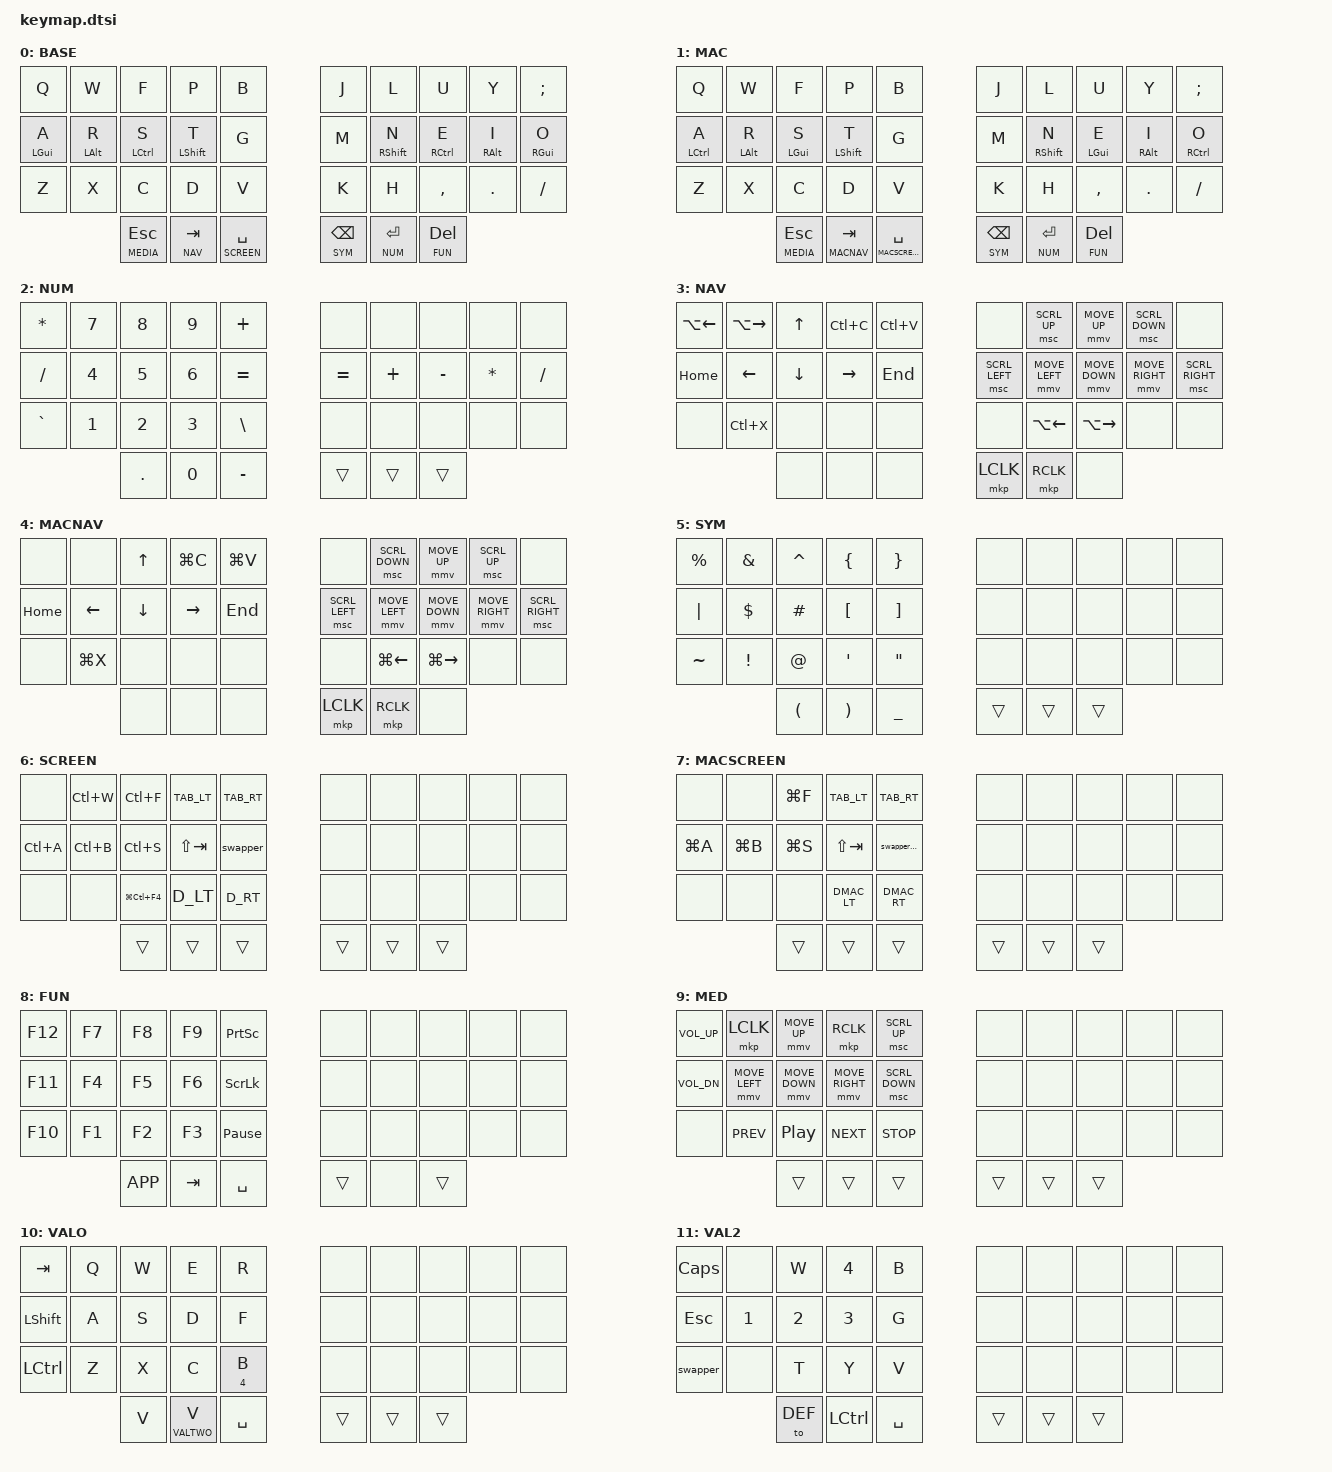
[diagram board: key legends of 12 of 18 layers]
 /*
 * Copyright (c) 2020 The ZMK Contributors
 *
 * SPDX-License-Identifier: MIT
 */

#include <behaviors.dtsi>
#include "zmk-helpers/helper.h"
#include <dt-bindings/zmk/keys.h>
#include <dt-bindings/zmk/bt.h>
#include <dt-bindings/zmk/outputs.h>
#include <dt-bindings/zmk/ext_power.h>


#include <dt-bindings/zmk/bt.h>

// #define _BT_SEL_KEYS_ &bt BT_SEL 0 &bt BT_SEL 1 &bt BT_SEL 2 &bt BT_SEL 3


#define DEF 0
#define MAC 1
#define NUM 2
#define NAV 3
#define MACNAV 4
#define SYM 5
#define SCREEN 6
#define MACSCREEN 7
#define FUN 8
#define MEDIA 9
#define VAL 10
#define VALTWO 11
#define EXTRA 12
#define TAP 13
#define MOUSE_KEYS 14
#define MOUSE_TP 15
#define MOUSE_TP_SET 16
#define SYS 17


/*
 * Defines to enable/disable features
 *
 * These defines allow us to conditionally enable and disable parts of the keymap config.
 *
 * For example, if we decide to build the firmware without the mouse features, we can
 * disable all the config options that rely on those forks and modules without having
 * to edit the entire keymap file manually every time.
 */

#define HAS_MOUSE_KEYS
#define HAS_MOUSE_TP

#ifdef HAS_MOUSE_KEYS
  #include <dt-bindings/zmk/mouse.h>
  #include <behaviors/mouse_keys.dtsi>
#endif  // HAS_MOUSE_KEYS

#ifdef HAS_MOUSE_TP
  // We store the trackpoint settings in a separate file
  // to make organization a little easier.
  #include "mouse_tp.dtsi"
#endif  // HAS_MOUSE_TP



// Adjust layer keys based on enabled features.
//
// This prevents build errors when we build the firmware
// without the mouse keys PR or the TP module.
#ifdef HAS_MOUSE_KEYS
  #define U_THUMB_INNER &mo MOUSE_KEYS
#else
  #define U_THUMB_INNER &none
#endif  // HAS_MOUSE_KEYS

#ifdef HAS_MOUSE_TP
  #define U_TOG_TP_SET &tog MOUSE_TP_SET
#else
  #define U_TOG_TP_SET &none
#endif  // HAS_MOUSE_TP


// Desktop and tab navigation shortcuts
#define D_LT   LC(LG(LEFT))
#define D_RT   LC(LG(RIGHT))
#define D_CL   LC(LG(F4))

//Mac desktop navigation shortcuts
#define DMAC_LT   LC(LEFT)
#define DMAC_RT   LC(RIGHT)

#define TAB_RT LC(TAB)
#define TAB_LT LC(LS(TAB))

// Extra key bindings
#define SWP_POS 13

&lt { quick_tap_ms = <250>; };
&lt { quick_tap_ms = <250>; };


#define QUICK_TAP_MS 175
#define TAPPING_TERM_MS 175

/* Timeless homerow mods */

// https://github.com/urob/zmk-config/tree/main#timeless-homerow-mods
#define KEYS_L LT0 LT1 LT2 LT3 LT4 LM0 LM1 LM2 LM3 LM4 LB0 LB1 LB2 LB3 LB4  // left hand
#define KEYS_R RT0 RT1 RT2 RT3 RT4 RM0 RM1 RM2 RM3 RM4 RB0 RB1 RB2 RB3 RB4  // right hand
#define THUMBS LH2 LH1 LH0 RH0 RH1 RH2                                      // thumbs

ZMK_HOLD_TAP(hml,
    flavor = "balanced";
    tapping-term-ms = <TAPPING_TERM_MS>;
    quick-tap-ms = <QUICK_TAP_MS>;
    require-prior-idle-ms = <150>;
    hold-trigger-key-positions = <KEYS_R THUMBS>;
    hold-trigger-on-release;
    bindings = <&kp>, <&kp>;
)

ZMK_HOLD_TAP(hmr,
    flavor = "balanced";
    tapping-term-ms = <TAPPING_TERM_MS>;
    quick-tap-ms = <QUICK_TAP_MS>;
    require-prior-idle-ms = <150>;
    hold-trigger-key-positions = <KEYS_L THUMBS>;
    hold-trigger-on-release;
    bindings = <&kp>, <&kp>;
)

#define QUICK_TAP_MS 175
/* Homerow mods */

/ {
    behaviors {
        bhm: balanced_homerow_mods {
            compatible = "zmk,behavior-hold-tap";
            #binding-cells = <2>;
            tapping-term-ms = <200>;    // <---[[moderate duration]]
            quick-tap-ms = <0>;
            flavor = "balanced";
            bindings = <&kp>, <&kp>;
        };
        // Swapper for smart alt+tab
        swapper: swapper {
            compatible = "zmk,behavior-tri-state";
            #binding-cells = <0>;
            bindings = <&kt LALT>, <&kp TAB>, <&kt LALT>;
            ignored-key-positions = <SWP_POS>;
        };
        swappermac: swappermac {
            compatible = "zmk,behavior-tri-state";
            #binding-cells = <0>;
            bindings = <&kt LGUI>, <&kp TAB>, <&kt LGUI>;
            ignored-key-positions = <SWP_POS>;
        };
    };
};
/ {
    conditional_layers {
        compatible = "zmk,conditional-layers";
        tri_layer {
            if-layers = <5 6>;
            then-layer = <14>;
        };
    };
};

/ {
    conditional_layers1 {
        compatible = "zmk,conditional-layers";
        tri_layer {
            if-layers = <5 7>;
            then-layer = <14>;
        };
    };
};

/ {
    macros {
        numdot: numdot {
            label = "ZM_numdot";
            compatible = "zmk,behavior-macro";
            #binding-cells = <0>;
            wait-ms = <40>;
            tap-ms = <40>;
            bindings
                = <&macro_press   &kp LALT>    
                , <&macro_tap     &kp KP_N4 &kp KP_N6>    
                , <&macro_release &kp LALT>
                ;
        };
        grtsgn: grtsgn {
            label = "ZM_grtsgn";
            compatible = "zmk,behavior-macro";
            #binding-cells = <0>;
            wait-ms = <40>;
            tap-ms = <40>;
            bindings
                = <&macro_press   &kp LALT>    
                , <&macro_tap     &kp KP_N6 &kp KP_N2>    
                , <&macro_release &kp LALT>
                ;
        };
    };
};

#include "combos.dtsi"

/ {
        keymap {
                compatible = "zmk,keymap";

                default_layer {  
                label = "BASE"; //DEFAULT
                bindings = <
                &kp Q                 &kp W         &kp F             &kp P             &kp B                      &kp J            &kp L              &kp U           &kp Y           &kp SEMI        
                &hml LGUI A           &hml LALT R   &hml LCTRL S      &hml LSHFT T      &kp G                      &kp M            &hmr RSHFT N       &hmr RCTRL E    &hmr RALT I     &hmr RGUI O     
                &kp Z                 &kp X         &kp C             &kp D             &kp V                      &kp K            &kp H              &kp COMMA       &kp DOT         &kp FSLH        
                                                    &lt MEDIA ESC     &lt NAV TAB       &lt SCREEN SPACE            &lt SYM BSPC     &lt NUM RET        &lt FUN DEL
                        >;
                };
                mac_layer {  
                label = "MAC"; //MAC DEFAULT
                bindings = <
                &kp Q                 &kp W         &kp F             &kp P             &kp B                      &kp J            &kp L              &kp U           &kp Y           &kp SEMI        
                &hml LCTRL A          &hml LALT R   &hml LGUI S       &hml LSHFT T      &kp G                      &kp M            &hmr RSHFT N       &hmr LGUI E     &hmr RALT I     &hmr RCTRL O     
                &kp Z                 &kp X         &kp C             &kp D             &kp V                      &kp K            &kp H              &kp COMMA       &kp DOT         &kp FSLH        
                                                    &lt MEDIA ESC     &lt MACNAV TAB       &lt MACSCREEN SPACE        &lt SYM BSPC     &lt NUM RET        &lt FUN DEL
                        >;
                };
                num_layer {    
                label = "NUM"; //NUM
                
                bindings = <
                &kp ASTRK             &kp N7        &kp N8            &kp N9            &kp PLUS                   &none            &none              &none           &none           &none           
                &kp SLASH             &kp N4        &kp N5            &kp N6            &kp EQUAL                  &kp EQUAL        &kp PLUS           &kp MINUS       &kp ASTRK       &kp SLASH            
                &kp GRAVE             &kp N1        &kp N2            &kp N3            &kp BSLH                   &none            &none              &none           &none           &none           
                                                    &kp DOT           &kp N0            &kp MINUS                  &trans           &trans             &trans
                        >;
                };
                nav_layer {    
                label = "NAV"; //NAV
                bindings = <
                &kp LA(LEFT)      &kp LA(RIGHT)     &kp UP            &kp LC(C)         &kp LC(V)                  &none            &msc SCRL_UP       &mmv MOVE_UP    &msc SCRL_DOWN  &none                
                &kp HOME              &kp LEFT      &kp DOWN          &kp RIGHT         &kp END                    &msc SCRL_LEFT   &mmv MOVE_LEFT     &mmv MOVE_DOWN  &mmv MOVE_RIGHT &msc SCRL_RIGHT           
                &none                 &kp LC(X)     &none             &none             &none                      &none            &kp LA(LEFT)       &kp LA(RIGHT)   &none           &none           
                                                    &none             &none             &none                      &mkp LCLK        &mkp RCLK          &none
                        >;  
                };
                macnav_layer {    
                label = "MACNAV"; //NAV
                bindings = <
                &none                     &none     &kp UP            &kp LG(C)         &kp LG(V)                  &none            &msc SCRL_DOWN     &mmv MOVE_UP    &msc SCRL_UP    &none                
                &kp HOME              &kp LEFT      &kp DOWN          &kp RIGHT         &kp END                    &msc SCRL_LEFT   &mmv MOVE_LEFT     &mmv MOVE_DOWN  &mmv MOVE_RIGHT &msc SCRL_RIGHT           
                &none                 &kp LG(X)     &none             &none             &none                      &none            &kp LG(LEFT)       &kp LG(RIGHT)   &none           &none                     
                                                    &none             &none             &none                      &mkp LCLK        &mkp RCLK          &none
                        >;  
                };
                sym_layer {   
                label = "SYM"; //SYM
                bindings = <
                &kp PRCNT             &kp AMPS      &kp CARET         &kp LBRC          &kp RBRC                   &none            &none              &none           &none           &none           
                &kp PIPE              &kp DLLR      &kp HASH          &kp LBKT          &kp RBKT                   &none            &none              &none           &none           &none           
                &kp TILDE             &kp EXCL      &kp AT            &kp SQT           &kp DOUBLE_QUOTES          &none            &none              &none           &none           &none           
                                                    &kp LPAR          &kp RPAR          &kp UNDER                  &trans           &trans             &trans 
                        >;
                };
                screen_layer {   
                label = "SCREEN"; //SCREEN
                bindings = <
                &none                   &kp LC(W)   &kp LC(F)         &kp TAB_LT         &kp TAB_RT                &none            &none              &none           &none           &none          
                &kp LC(A)               &kp LC(B)   &kp LC(S)         &kp LS(TAB)        &swapper                  &none            &none              &none           &none           &none         
                &none                   &none       &kp LG(LC(F4))    &kp D_LT           &kp D_RT                  &none            &none              &none           &none           &none          
                                                    &trans            &trans             &trans                    &trans           &trans             &trans
                        >;
                };
                macscreen_layer {   
                label = "MACSCREEN"; //MAC SCREEN
                bindings = <
                &none                   &none       &kp LG(F)         &kp TAB_LT         &kp TAB_RT                &none            &none              &none           &none           &none          
                &kp LG(A)               &kp LG(B)   &kp LG(S)         &kp LS(TAB)        &swappermac               &none            &none              &none           &none           &none         
                &none                   &none       &none             &kp DMAC_LT        &kp DMAC_RT               &none            &none              &none           &none           &none          
                                                    &trans            &trans             &trans                    &trans           &trans             &trans
                        >;
                };
                fun_layer {  
                label = "FUN"; //FUN
                bindings = <
                &kp F12               &kp F7        &kp F8            &kp F9            &kp PSCRN                  &none            &none              &none           &none           &none           
                &kp F11               &kp F4        &kp F5            &kp F6            &kp SLCK                   &none            &none              &none           &none           &none           
                &kp F10               &kp F1        &kp F2            &kp F3            &kp PAUSE_BREAK            &none            &none              &none           &none           &none           
                                                    &kp K_APP         &kp TAB           &kp SPACE                  &trans           &none              &trans
                        >;
                };
                media_layer {  
                label = "MED"; //MEDIA         
                bindings = <
                &kp C_VOL_UP          &mkp LCLK     &mmv MOVE_UP      &mkp RCLK         &msc SCRL_UP               &none            &none              &none           &none           &none           
                &kp C_VOL_DN          &mmv MOVE_LEFT &mmv MOVE_DOWN   &mmv MOVE_RIGHT   &msc SCRL_DOWN             &none            &none              &none           &none           &none           
                &none                 &kp C_PREV    &kp C_PP          &kp C_NEXT        &kp C_STOP                 &none            &none              &none           &none           &none           
                                                    &trans            &trans            &trans                     &trans           &trans             &trans
                        >;
                };
                // media_layer {  
                // label = "MED"; //MEDIA  
                // bindings = <
                // &none                 &none         &kp C_VOL_UP      &none             &kp C_MUTE                 &none            &none              &none           &none           &none           
                // &none                 &kp C_PREV    &kp C_VOL_DN      &kp C_NEXT        &kp C_PP                   &none            &none              &none           &none           &none           
                // &none                 &none         &none             &none             &kp C_STOP                 &none            &none              &none           &none           &none           
                //                                     &trans            &trans            &trans                     &trans           &trans             &trans
                //         >;
                // };

                val_layer {  
                label = "VALO"; //VAL
                bindings = <
                &kp TAB               &kp Q         &kp W             &kp E             &kp R                      &none            &none              &none           &none           &none           
                &kp LSHFT             &kp A         &kp S             &kp D             &kp F                      &none            &none              &none           &none           &none           
                &kp LCTRL             &kp Z         &kp X             &kp C             &bhm N4 B                  &none            &none              &none           &none           &none          
                                                    &kp V             &lt VALTWO V      &kp SPACE                  &trans           &trans             &trans
                        >;
                };
                valtwo_layer {  
                label = "VAL2"; //VALTWO
                bindings = <
                &kp CAPSLOCK         &none          &kp W             &kp N4            &kp B                      &none            &none              &none           &none           &none           
                &kp ESC              &kp N1         &kp N2            &kp N3            &kp G                      &none            &none              &none           &none           &none           
                &swapper             &none          &kp T             &kp Y             &kp V                      &none            &none              &none           &none           &none           
                                                    &to DEF           &kp LCTRL         &kp SPACE                  &trans           &trans             &trans
                        >;
                };
                extra_layer {    
                label = "EXTRA"; //EXTRA
                bindings = <
                &kp Q               &kp W           &kp E             &kp R             &kp T                      &kp Y            &kp U              &kp I           &kp O           &kp P            
                &kp A               &kp S           &kp D             &kp F             &kp G                      &kp H            &kp J              &kp K           &kp L           &kp SEMI        
                &kp Z               &kp X           &kp C             &kp V             &kp B                      &kp N            &kp M              &kp COMMA       &kp DOT         &kp FSLH        
                                                    &kp ESC           &kp TAB           &kp SPACE                  &kp BSPC         &kp RET            &to DEF 
                        >; 
                };
                tap_layer {  
                label = "TAP"; //TAP
                bindings = <
                &kp Q                 &kp W         &kp F             &kp P             &kp B                      &kp J            &kp L              &kp U           &kp Y           &kp SEMI        
                &kp A                 &kp R         &kp S             &kp T             &kp G                      &kp M            &kp N              &kp E           &kp I           &kp O     
                &kp Z                 &kp X         &kp C             &kp D             &kp V                      &kp K            &kp H              &kp COMMA       &kp DOT         &kp FSLH        
                                                    &kp ESC           &kp TAB           &kp SPACE                  &kp BSPC         &kp RET            &kp DEL
                        >;
                };
                sys_layer {    
                label = "SYS"; //SYS
                bindings = <
                &bt BT_CLR          &none           &none             &none             &to DEF                   &to DEF           &none              &none           &none           &bt BT_CLR          
                &none               &none           &none             &none             &to MAC                   &bt BT_SEL 0      &bt BT_SEL 1       &bt BT_SEL 2    &bt BT_SEL 3    &bt BT_SEL 4      
                &bootloader     &ext_power EP_ON    &out OUT_USB      &out OUT_BLE      &sys_reset                &sys_reset        &none              &none      &ext_power EP_ON     &bootloader            
                                                    &trans            &trans            &trans                    &trans            &trans             &trans
                        >; 
                };

                #ifdef HAS_MOUSE_KEYS

    MouseKeys_layer {
      display-name = "MouseKeys";
      bindings = <
// ╭────────────────────────┬────────────────────────┬────────────────────────┬────────────────────────┬────────────────────────┬────────────────────────╮    ╭────────────────────────┬────────────────────────┬────────────────────────┬────────────────────────┬────────────────────────┬────────────────────────╮
     U_TOG_TP_SET             U_TOG_TP_SET             &none                    &mmv MOVE_UP             &msc SCRL_UP             &none                         &none                    &msc SCRL_UP             &mmv MOVE_UP             &none                    U_TOG_TP_SET              U_TOG_TP_SET
// ├────────────────────────┼────────────────────────┼────────────────────────┼────────────────────────┼────────────────────────┼────────────────────────┤    ├────────────────────────┼────────────────────────┼────────────────────────┼────────────────────────┼────────────────────────┼────────────────────────┤
     &trans                   &none                    &mmv MOVE_LEFT           &mmv MOVE_DOWN           &mmv MOVE_RIGHT          &none                         &none                    &mmv MOVE_LEFT           &mmv MOVE_DOWN           &mmv MOVE_RIGHT          &none                     &trans
// ├────────────────────────┼────────────────────────┼────────────────────────┼────────────────────────┼────────────────────────┼────────────────────────┤    ├────────────────────────┼────────────────────────┼────────────────────────┼────────────────────────┼────────────────────────┼────────────────────────┤
     &trans                   &none                    &none                    &none                    &msc SCRL_DOWN           &none                         &none                    &msc SCRL_DOWN           &none                    &none                    &trans                    &trans
// ╰────────────────────────┴────────────────────────┴────────────────────────┴────────────────────────┼────────────────────────┼────────────────────────┤    ├────────────────────────┼────────────────────────┼────────────────────────┼────────────────────────┴────────────────────────┼────────────────────────╯
                                                                                &mkp MCLK                &mkp LCLK                &mkp RCLK                     &mkp MCLK                &mkp LCLK                &mkp RCLK
//                                                                            ╰────────────────────────┴────────────────────────┴────────────────────────╯    ╰────────────────────────┴────────────────────────┴────────────────────────╯
      >;
    };

#endif

#ifdef HAS_MOUSE_TP

    // Automatically activated when the mouse or trackpoint moves.
    // Configured in `mouse_tp.dtsi`.
    MouseTP_layer {
      display-name = "TP";
      bindings = <
// ╭────────────────────────┬────────────────────────┬────────────────────────┬────────────────────────┬────────────────────────┬────────────────────────╮    ╭────────────────────────┬────────────────────────┬────────────────────────┬────────────────────────┬────────────────────────┬────────────────────────╮
     U_TOG_TP_SET             U_TOG_TP_SET             &trans                   &trans                   &msc SCRL_UP             &trans                        &trans                   &trans                   &trans                   &trans                   U_TOG_TP_SET              U_TOG_TP_SET
// ├────────────────────────┼────────────────────────┼────────────────────────┼────────────────────────┼────────────────────────┼────────────────────────┤    ├────────────────────────┼────────────────────────┼────────────────────────┼────────────────────────┼────────────────────────┼────────────────────────┤
     &trans                   &trans                   &trans                   &trans                   &trans                   &trans                        &trans                   &trans                   &trans                   &trans                   &trans                    &trans
// ├────────────────────────┼────────────────────────┼────────────────────────┼────────────────────────┼────────────────────────┼────────────────────────┤    ├────────────────────────┼────────────────────────┼────────────────────────┼────────────────────────┼────────────────────────┼────────────────────────┤
     &trans                   &trans                   &trans                   &trans                   &msc SCRL_DOWN           &trans                        &trans                   &trans                   &trans                   &trans                   &trans                    &trans
// ╰────────────────────────┴────────────────────────┴────────────────────────┴────────────────────────┼────────────────────────┼────────────────────────┤    ├────────────────────────┼────────────────────────┼────────────────────────┼────────────────────────┴────────────────────────┼────────────────────────╯
                                                                                &mkp MCLK                &mkp LCLK                &mkp RCLK                     &mkp MCLK                &mkp LCLK                &mkp RCLK
//                                                                            ╰────────────────────────┴────────────────────────┴────────────────────────╯    ╰────────────────────────┴────────────────────────┴────────────────────────╯
      >;
    };

    // You can find the defines for the actual key press behaviors in `mouse_tp.dtsi`.
    MouseSettings_layer {
      display-name = "TP Set";
      bindings = <
// ╭────────────────────────┬────────────────────────┬────────────────────────┬────────────────────────┬────────────────────────┬────────────────────────╮    ╭────────────────────────┬────────────────────────┬────────────────────────┬────────────────────────┬────────────────────────┬────────────────────────╮
     U_TOG_TP_SET             U_TOG_TP_SET             &none                    U_MSS_TP_S_D             U_MSS_TP_S_I             U_MSS_TP_PT_I                 U_MSS_TP_PT_I            U_MSS_TP_S_D             U_MSS_TP_S_I             &none                    U_TOG_TP_SET              U_TOG_TP_SET
// ├────────────────────────┼────────────────────────┼────────────────────────┼────────────────────────┼────────────────────────┼────────────────────────┤    ├────────────────────────┼────────────────────────┼────────────────────────┼────────────────────────┼────────────────────────┼────────────────────────┤
     U_MSS_RESET              U_MSS_RESET              &none                    U_MSS_TP_NI_D            U_MSS_TP_NI_I            U_MSS_TP_PT_D                 U_MSS_TP_PT_D            U_MSS_TP_NI_D            U_MSS_TP_NI_I            &none                    U_MSS_RESET               U_MSS_RESET
// ├────────────────────────┼────────────────────────┼────────────────────────┼────────────────────────┼────────────────────────┼────────────────────────┤    ├────────────────────────┼────────────────────────┼────────────────────────┼────────────────────────┼────────────────────────┼────────────────────────┤
     U_MSS_LOG                U_MSS_LOG                &none                    U_MSS_TP_V6_D            U_MSS_TP_V6_I            &none                         &none                    U_MSS_TP_V6_D            U_MSS_TP_V6_I            &none                    U_MSS_LOG                 U_MSS_LOG
// ╰────────────────────────┴────────────────────────┴────────────────────────┴────────────────────────┼────────────────────────┼────────────────────────┤    ├────────────────────────┼────────────────────────┼────────────────────────┼────────────────────────┴────────────────────────┼────────────────────────╯
                                                                                &trans                   &mkp LCLK                &mkp RCLK                     &none                    &mkp LCLK                &mkp RCLK
//                                                                            ╰────────────────────────┴────────────────────────┴────────────────────────╯    ╰────────────────────────┴────────────────────────┴────────────────────────╯
      >;
    };

#endif
        };
};
